CM_ "AUTOGENERATED FILE, DO NOT EDIT";

CM_ "Imported file _community.dbc starts here";
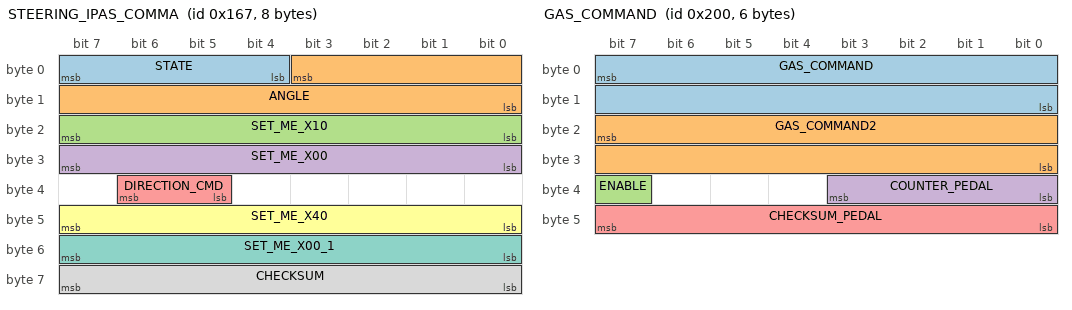
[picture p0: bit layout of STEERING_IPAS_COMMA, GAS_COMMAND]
BO_ 359 STEERING_IPAS_COMMA: 8 IPAS
 SG_ STATE : 7|4@0+ (1,0) [0|15] "" XXX
 SG_ ANGLE : 3|12@0- (1.5,0) [-510|510] "deg" XXX
 SG_ SET_ME_X10 : 23|8@0+ (1,0) [0|255] "" XXX
 SG_ SET_ME_X00 : 31|8@0+ (1,0) [0|255] "" XXX
 SG_ DIRECTION_CMD : 38|2@0+ (1,0) [0|3] "" XXX
 SG_ SET_ME_X40 : 47|8@0+ (1,0) [0|255] "" XXX
 SG_ SET_ME_X00_1 : 55|8@0+ (1,0) [0|255] "" XXX
 SG_ CHECKSUM : 63|8@0+ (1,0) [0|255] "" XXX

CM_ "BO_ STEERING_IPAS_COMMA: Copy of msg 614 so we can do angle control while the Park Assist ECU is connected (Panda spoofs 614 with 359 on connector J70). Note that addresses 0x266 and 0x167 are checksum-invariant";

BO_ 512 GAS_COMMAND: 6 EON
 SG_ GAS_COMMAND : 7|16@0+ (0.159375,-75.555) [0|1] "" INTERCEPTOR
 SG_ GAS_COMMAND2 : 23|16@0+ (0.159375,-151.111) [0|1] "" INTERCEPTOR
 SG_ ENABLE : 39|1@0+ (1,0) [0|1] "" INTERCEPTOR
 SG_ COUNTER_PEDAL : 35|4@0+ (1,0) [0|15] "" INTERCEPTOR
 SG_ CHECKSUM_PEDAL : 47|8@0+ (1,0) [0|255] "" INTERCEPTOR

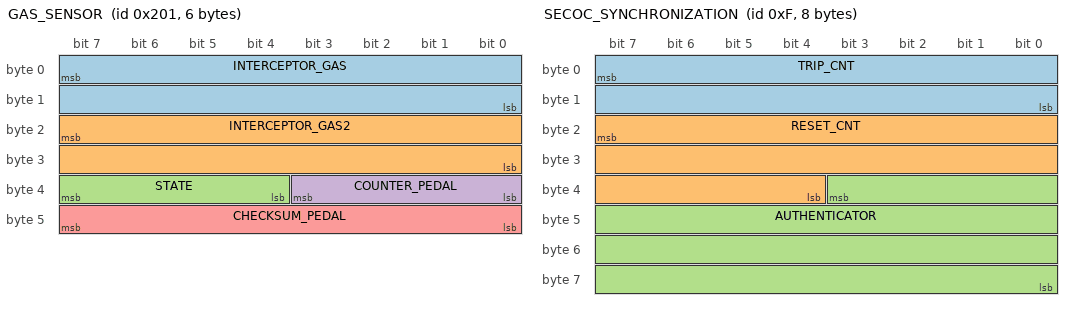
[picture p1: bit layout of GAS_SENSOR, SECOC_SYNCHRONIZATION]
BO_ 513 GAS_SENSOR: 6 INTERCEPTOR
 SG_ INTERCEPTOR_GAS : 7|16@0+ (1,0) [0|1] "" EON
 SG_ INTERCEPTOR_GAS2 : 23|16@0+ (1,0) [0|1] "" EON
 SG_ STATE : 39|4@0+ (1,0) [0|15] "" EON
 SG_ COUNTER_PEDAL : 35|4@0+ (1,0) [0|15] "" EON
 SG_ CHECKSUM_PEDAL : 47|8@0+ (1,0) [0|255] "" EON

VAL_ 513 STATE 5 "FAULT_TIMEOUT" 4 "FAULT_STARTUP" 3 "FAULT_SCE" 2 "FAULT_SEND" 1 "FAULT_BAD_CHECKSUM" 0 "NO_FAULT" ;

BO_ 35 SECONDARY_STEER_ANGLE: 8 XXX
 SG_ ZORRO_STEER : 7|24@0- (0.004901594652,0) [-500|500] "" XXX

CM_ "BO_ SECONDARY_STEER_ANGLE: ZSS is a high-precision steering angle sensor that can replace the lower resolution sensor in most TSS1 Toyotas. Learn more: https://github.com/commaai/openpilot/wiki/Toyota-Lexus#zorro-steering-sensor-zss";

BO_ 767 SDSU: 8 XXX
 SG_ FD_BUTTON : 7|1@0+ (1,0) [0|1] "" XXX
 SG_ STATE : 23|4@0+ (1,0) [0|15] "" XXX

CM_ "BO_ SDSU: The sDSU is a modified DSU for use in TSS-P Toyotas. Learn more: https://github.com/RetroPilot/ocelot/tree/main/firmware/smart_dsu";
CM_ SG_ 767 FD_BUTTON "The follow distance button signal as forwarded by the sdsu";

VAL_ 767 STATE 7 "STATE_AEB_CTRL" 6 "FAULT_INVALID" 5 "FAULT_TIMEOUT" 4 "FAULT_STARTUP" 3 "FAULT_SCE" 2 "FAULT_SEND" 1 "FAULT_BAD_CHECKSUM" 0 "NO_FAULT" ;

CM_ "toyota_rav4_prime.dbc starts here";
VERSION ""

NS_ :

BS_:

BU_: XXX DSU HCU EPS IPAS CGW BGM

BO_ 15 SECOC_SYNCHRONIZATION: 8 XXX
 SG_ TRIP_CNT : 7|16@0+ (1,0) [0|65535] "" XXX
 SG_ RESET_CNT : 23|20@0+ (1,0) [0|65535] "" XXX
 SG_ AUTHENTICATOR : 35|28@0+ (1,0) [0|268435455] "" XXX

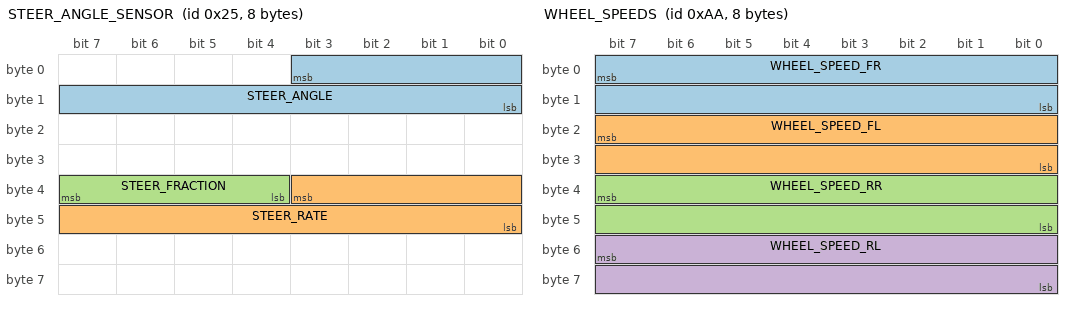
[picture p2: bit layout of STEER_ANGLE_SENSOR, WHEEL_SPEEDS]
BO_ 37 STEER_ANGLE_SENSOR: 8 XXX
 SG_ STEER_ANGLE : 3|12@0- (1.5,0) [-500|500] "deg" XXX
 SG_ STEER_RATE : 35|12@0- (1,0) [-2000|2000] "deg/s" XXX
 SG_ STEER_FRACTION : 39|4@0- (0.1,0) [-0.7|0.7] "deg" XXX

BO_ 170 WHEEL_SPEEDS: 8 XXX
 SG_ WHEEL_SPEED_FR : 7|16@0+ (0.01,-67.67) [0|250] "km/h" XXX
 SG_ WHEEL_SPEED_FL : 23|16@0+ (0.01,-67.67) [0|250] "km/h" XXX
 SG_ WHEEL_SPEED_RR : 39|16@0+ (0.01,-67.67) [0|250] "km/h" XXX
 SG_ WHEEL_SPEED_RL : 55|16@0+ (0.01,-67.67) [0|250] "km/h" XXX

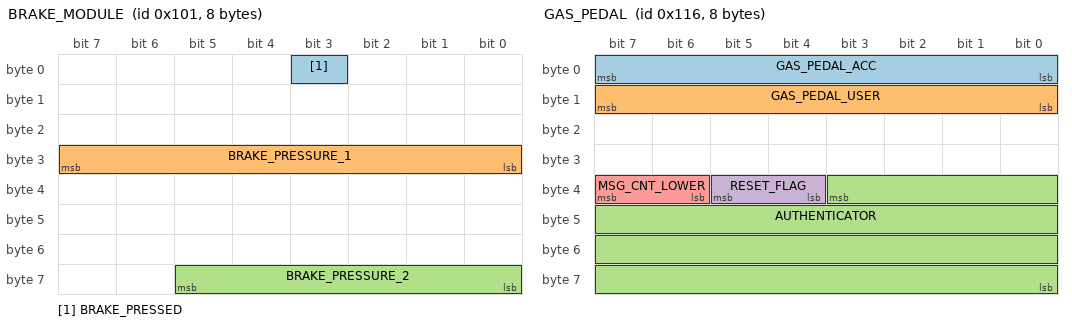
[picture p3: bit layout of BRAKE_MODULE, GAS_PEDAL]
BO_ 257 BRAKE_MODULE: 8 XXX
 SG_ BRAKE_PRESSED : 3|1@0+ (1,0) [0|1] "" XXX
 SG_ BRAKE_PRESSURE_1 : 31|8@0+ (1,0) [0|15] "" XXX
 SG_ BRAKE_PRESSURE_2 : 61|6@0+ (1,0) [0|63] "" XXX

BO_ 278 GAS_PEDAL: 8 XXX
 SG_ GAS_PEDAL_ACC : 7|8@0+ (0.005,0) [0|255] "" XXX
 SG_ GAS_PEDAL_USER : 15|8@0+ (0.005,0) [0|255] "" XXX
 SG_ AUTHENTICATOR : 35|28@0+ (1,0) [0|268435455] "" XXX
 SG_ RESET_FLAG : 37|2@0+ (1,0) [0|3] "" XXX
 SG_ MSG_CNT_LOWER : 39|2@0+ (1,0) [0|3] "" XXX

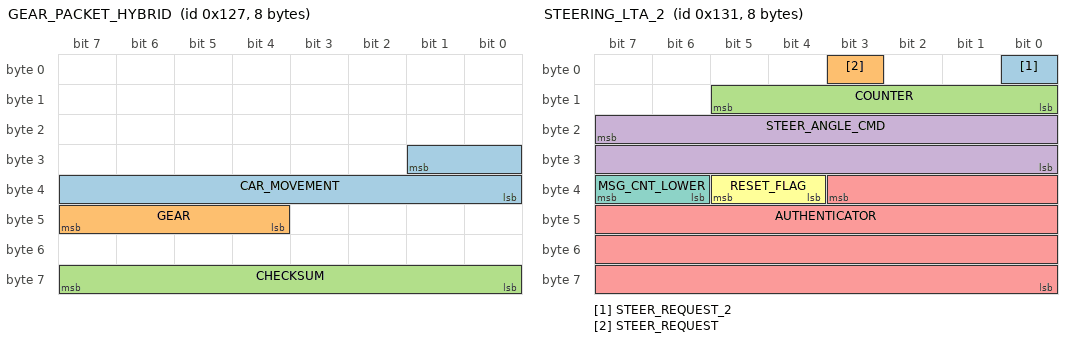
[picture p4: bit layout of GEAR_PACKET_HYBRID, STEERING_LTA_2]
BO_ 295 GEAR_PACKET_HYBRID: 8 XXX
 SG_ CAR_MOVEMENT : 25|10@0- (1,0) [0|255] "" XXX
 SG_ GEAR : 47|4@0+ (1,0) [0|15] "" XXX
 SG_ CHECKSUM : 63|8@0+ (1,0) [0|255] "" XXX

BO_ 305 STEERING_LTA_2: 8 XXX
 SG_ STEER_REQUEST_2 : 0|1@0+ (1,0) [0|1] "" XXX
 SG_ STEER_REQUEST : 3|1@0+ (1,0) [0|1] "" XXX
 SG_ COUNTER : 13|6@0+ (1,0) [0|63] "" XXX
 SG_ STEER_ANGLE_CMD : 23|16@0- (0.0573,0) [0|65535] "" XXX
 SG_ AUTHENTICATOR : 35|28@0+ (1,0) [0|268435455] "" XXX
 SG_ RESET_FLAG : 37|2@0+ (1,0) [0|3] "" XXX
 SG_ MSG_CNT_LOWER : 39|2@0+ (1,0) [0|3] "" XXX

BO_ 353 DSU_SPEED: 7 XXX
 SG_ FORWARD_SPEED : 15|16@0- (0.00390625,-30) [0|255] "km/h" XXX

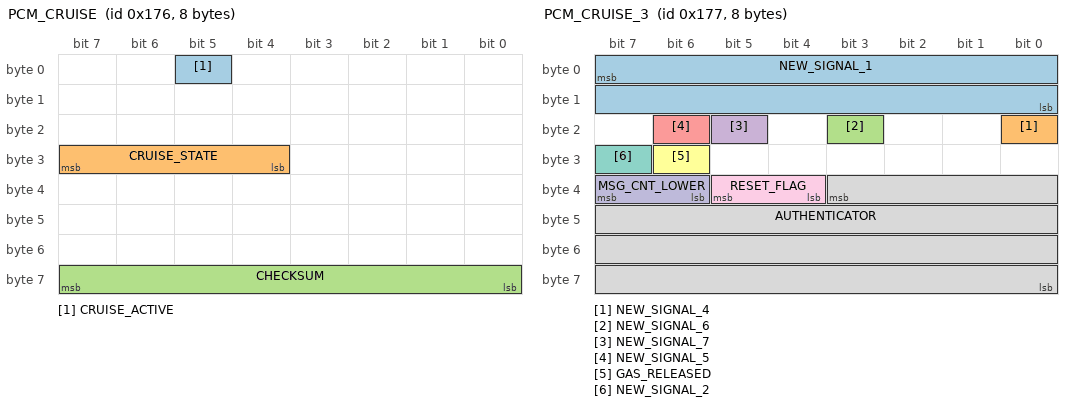
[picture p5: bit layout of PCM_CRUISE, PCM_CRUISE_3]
BO_ 374 PCM_CRUISE: 8 XXX
 SG_ CRUISE_ACTIVE : 5|1@0+ (1,0) [0|1] "" XXX
 SG_ CRUISE_STATE : 31|4@0+ (1,0) [0|1] "" XXX
 SG_ CHECKSUM : 63|8@0+ (1,0) [0|255] "" XXX

BO_ 375 PCM_CRUISE_3: 8 XXX
 SG_ NEW_SIGNAL_1 : 7|16@0- (1,0) [0|65535] "" XXX
 SG_ NEW_SIGNAL_4 : 16|1@0+ (1,0) [0|1] "" XXX
 SG_ NEW_SIGNAL_6 : 19|1@0+ (1,0) [0|1] "" XXX
 SG_ NEW_SIGNAL_7 : 21|1@0+ (1,0) [0|1] "" XXX
 SG_ NEW_SIGNAL_5 : 22|1@0+ (1,0) [0|1] "" XXX
 SG_ GAS_RELEASED : 30|1@0+ (1,0) [0|1] "" XXX
 SG_ NEW_SIGNAL_2 : 31|1@0+ (1,0) [0|1] "" XXX
 SG_ AUTHENTICATOR : 35|28@0+ (1,0) [0|268435455] "" XXX
 SG_ RESET_FLAG : 37|2@0+ (1,0) [0|3] "" XXX
 SG_ MSG_CNT_LOWER : 39|2@0+ (1,0) [0|3] "" XXX

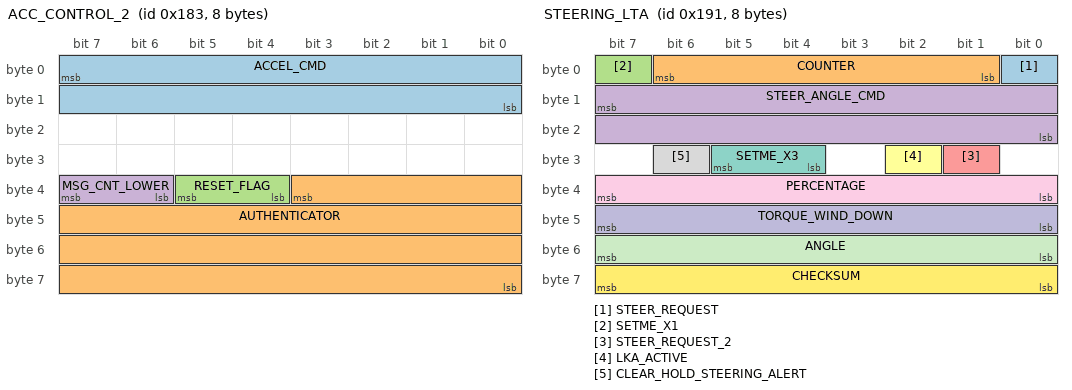
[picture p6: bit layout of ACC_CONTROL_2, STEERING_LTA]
BO_ 387 ACC_CONTROL_2: 8 XXX
 SG_ ACCEL_CMD : 7|16@0- (0.001,0) [-20|20] "m/s^2" HCU
 SG_ AUTHENTICATOR : 35|28@0+ (1,0) [0|268435455] "" XXX
 SG_ RESET_FLAG : 37|2@0+ (1,0) [0|3] "" XXX
 SG_ MSG_CNT_LOWER : 39|2@0+ (1,0) [0|3] "" XXX

BO_ 401 STEERING_LTA: 8 XXX
 SG_ STEER_REQUEST : 0|1@0+ (1,0) [0|1] "" XXX
 SG_ COUNTER : 6|6@0+ (1,0) [0|255] "" XXX
 SG_ SETME_X1 : 7|1@0+ (1,0) [0|1] "" XXX
 SG_ STEER_ANGLE_CMD : 15|16@0- (0.0573,0) [-540|540] "" XXX
 SG_ STEER_REQUEST_2 : 25|1@0+ (1,0) [0|1] "" XXX
 SG_ LKA_ACTIVE : 26|1@0+ (1,0) [0|1] "" XXX
 SG_ SETME_X3 : 29|2@0+ (1,0) [0|3] "" XXX
 SG_ CLEAR_HOLD_STEERING_ALERT : 30|1@0+ (1,0) [0|1] "" XXX
 SG_ PERCENTAGE : 39|8@0+ (1,0) [0|255] "" XXX
 SG_ TORQUE_WIND_DOWN : 47|8@0+ (1,0) [0|255] "" XXX
 SG_ ANGLE : 55|8@0- (0.5,0) [0|255] "" XXX
 SG_ CHECKSUM : 63|8@0+ (1,0) [0|255] "" XXX

BO_ 418 CRUISE_RELATED: 8 XXX
 SG_ CRUISE_ACTIVE : 7|1@0+ (1,0) [0|1] "" XXX
 SG_ CHECKSUM : 63|8@0+ (1,0) [0|255] "" XXX

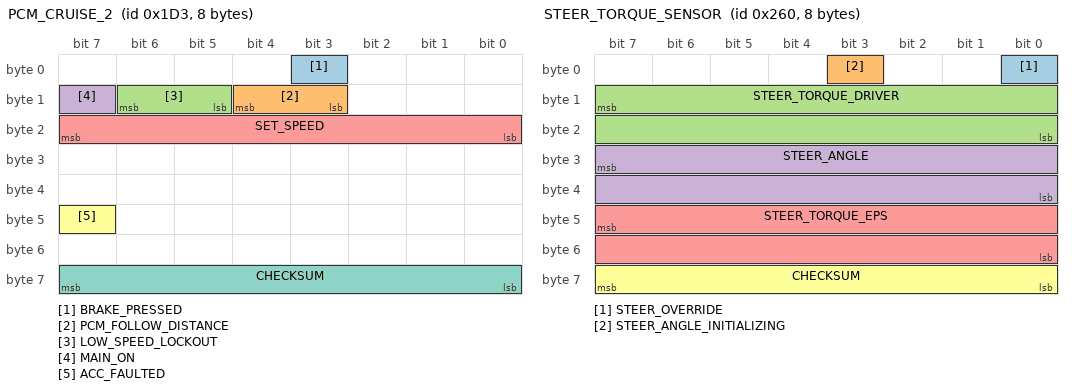
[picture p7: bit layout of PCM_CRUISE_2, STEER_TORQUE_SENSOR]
BO_ 467 PCM_CRUISE_2: 8 XXX
 SG_ BRAKE_PRESSED : 3|1@0+ (1,0) [0|1] "" XXX
 SG_ PCM_FOLLOW_DISTANCE : 12|2@0+ (1,0) [0|3] "" XXX
 SG_ LOW_SPEED_LOCKOUT : 14|2@0+ (1,0) [0|3] "" XXX
 SG_ MAIN_ON : 15|1@0+ (1,0) [0|1] "" XXX
 SG_ SET_SPEED : 23|8@0+ (1,0) [0|255] "km/h" XXX
 SG_ ACC_FAULTED : 47|1@0+ (1,0) [0|1] "" XXX
 SG_ CHECKSUM : 63|8@0+ (1,0) [0|255] "" XXX

BO_ 608 STEER_TORQUE_SENSOR: 8 XXX
 SG_ STEER_OVERRIDE : 0|1@0+ (1,0) [0|1] "" XXX
 SG_ STEER_ANGLE_INITIALIZING : 3|1@0+ (1,0) [0|1] "" XXX
 SG_ STEER_TORQUE_DRIVER : 15|16@0- (1,0) [-32768|32767] "" XXX
 SG_ STEER_ANGLE : 31|16@0- (0.0573,0) [-500|500] "" XXX
 SG_ STEER_TORQUE_EPS : 47|16@0- (1,0) [-32768|32767] "" XXX
 SG_ CHECKSUM : 63|8@0+ (1,0) [0|255] "" XXX

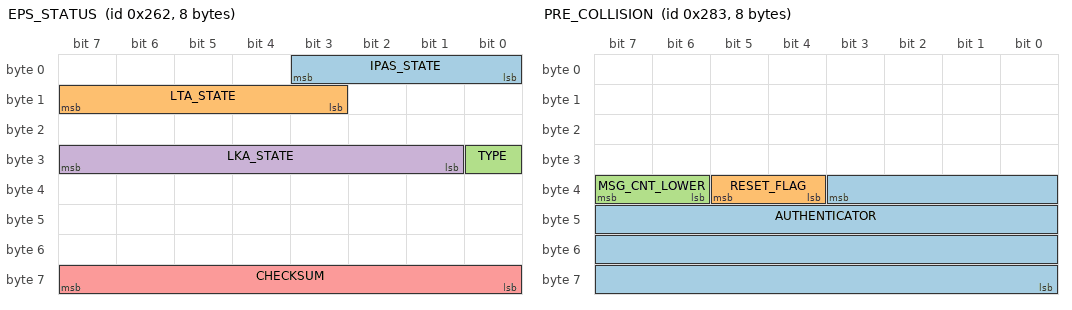
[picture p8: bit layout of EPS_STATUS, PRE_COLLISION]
BO_ 610 EPS_STATUS: 8 EPS
 SG_ IPAS_STATE : 3|4@0+ (1,0) [0|15] "" XXX
 SG_ LTA_STATE : 15|5@0+ (1,0) [0|31] "" XXX
 SG_ TYPE : 24|1@0+ (1,0) [0|1] "" XXX
 SG_ LKA_STATE : 31|7@0+ (1,0) [0|127] "" XXX
 SG_ CHECKSUM : 63|8@0+ (1,0) [0|255] "" XXX

BO_ 643 PRE_COLLISION: 8 DSU
 SG_ AUTHENTICATOR : 35|28@0+ (1,0) [0|268435455] "" XXX
 SG_ RESET_FLAG : 37|2@0+ (1,0) [0|3] "" XXX
 SG_ MSG_CNT_LOWER : 39|2@0+ (1,0) [0|3] "" XXX

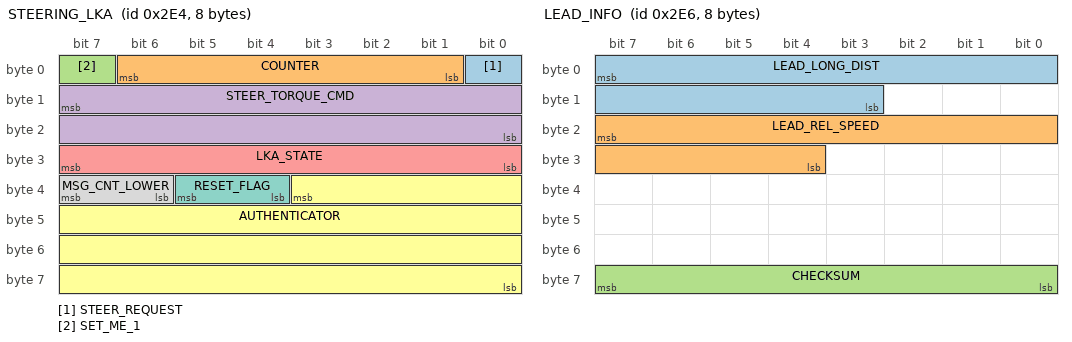
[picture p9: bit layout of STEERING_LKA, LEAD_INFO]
BO_ 740 STEERING_LKA: 8 XXX
 SG_ STEER_REQUEST : 0|1@0+ (1,0) [0|1] "" XXX
 SG_ COUNTER : 6|6@0+ (1,0) [0|63] "" XXX
 SG_ SET_ME_1 : 7|1@0+ (1,0) [0|1] "" XXX
 SG_ STEER_TORQUE_CMD : 15|16@0- (1,0) [0|65535] "" XXX
 SG_ LKA_STATE : 31|8@0+ (1,0) [0|255] "" XXX
 SG_ AUTHENTICATOR : 35|28@0+ (1,0) [0|268435455] "" XXX
 SG_ RESET_FLAG : 37|2@0+ (1,0) [0|3] "" XXX
 SG_ MSG_CNT_LOWER : 39|2@0+ (1,0) [0|3] "" XXX

BO_ 742 LEAD_INFO: 8 DSU
 SG_ LEAD_LONG_DIST : 7|13@0+ (0.05,0) [0|300] "m" HCU
 SG_ LEAD_REL_SPEED : 23|12@0- (0.025,0) [-100|100] "m/s" HCU
 SG_ CHECKSUM : 63|8@0+ (1,0) [0|255] "" HCU

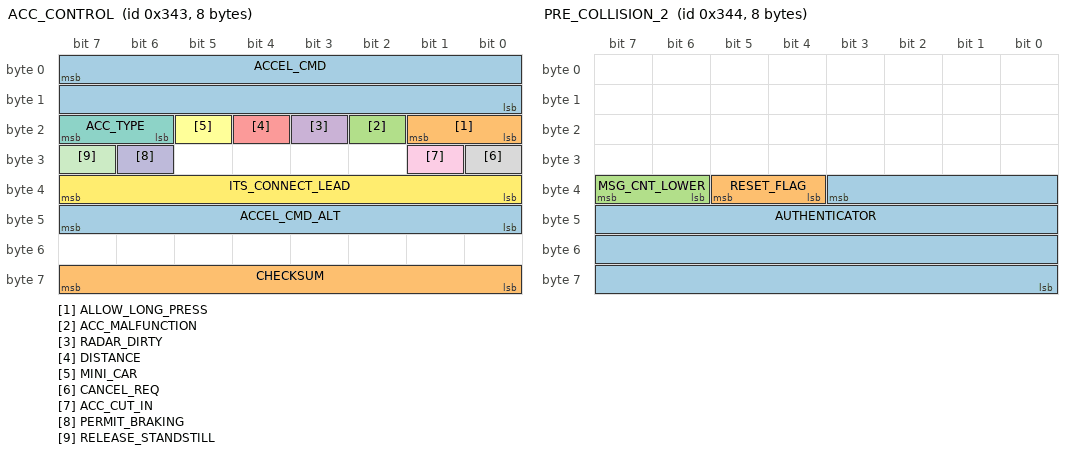
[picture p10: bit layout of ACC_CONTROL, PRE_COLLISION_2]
BO_ 835 ACC_CONTROL: 8 DSU
 SG_ ACCEL_CMD : 7|16@0- (0.001,0) [-20|20] "m/s^2" HCU
 SG_ ALLOW_LONG_PRESS : 17|2@0+ (1,0) [0|2] "" XXX
 SG_ ACC_MALFUNCTION : 18|1@0+ (1,0) [0|0] "" XXX
 SG_ RADAR_DIRTY : 19|1@0+ (1,0) [0|1] "" XXX
 SG_ DISTANCE : 20|1@0+ (1,0) [0|1] "" XXX
 SG_ MINI_CAR : 21|1@0+ (1,0) [0|1] "" XXX
 SG_ ACC_TYPE : 23|2@0+ (1,0) [0|3] "" HCU
 SG_ CANCEL_REQ : 24|1@0+ (1,0) [0|1] "" HCU
 SG_ ACC_CUT_IN : 25|1@0+ (1,0) [0|1] "" XXX
 SG_ PERMIT_BRAKING : 30|1@0+ (1,0) [0|1] "" HCU
 SG_ RELEASE_STANDSTILL : 31|1@0+ (1,0) [0|1] "" HCU
 SG_ ITS_CONNECT_LEAD : 39|8@0+ (1,0) [0|1] "" Vector__XXX
 SG_ ACCEL_CMD_ALT : 47|8@0- (0.05,0) [0|0] "m/s^2" XXX
 SG_ CHECKSUM : 63|8@0+ (1,0) [0|255] "" XXX

BO_ 836 PRE_COLLISION_2: 8 DSU
 SG_ AUTHENTICATOR : 35|28@0+ (1,0) [0|268435455] "" XXX
 SG_ RESET_FLAG : 37|2@0+ (1,0) [0|3] "" XXX
 SG_ MSG_CNT_LOWER : 39|2@0+ (1,0) [0|3] "" XXX

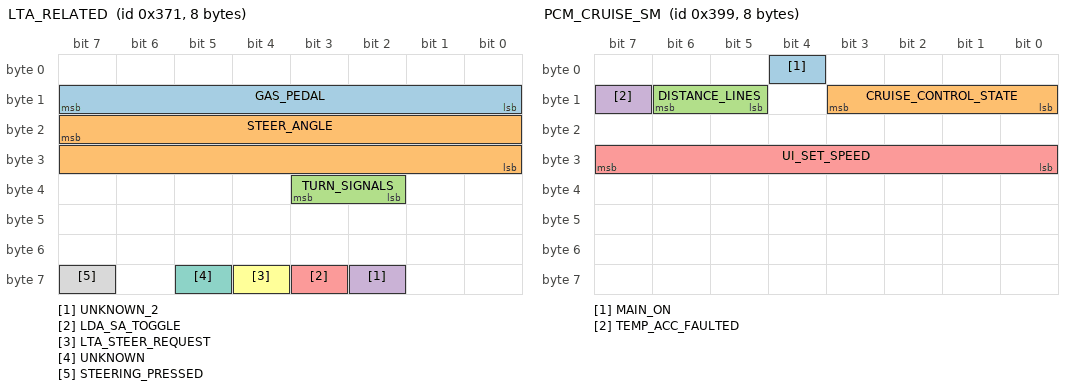
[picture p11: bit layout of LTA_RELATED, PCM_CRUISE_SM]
BO_ 881 LTA_RELATED: 8 FCM
 SG_ GAS_PEDAL : 15|8@0+ (0.005,0) [0|1] "" XXX
 SG_ STEER_ANGLE : 23|16@0- (0.0573,0) [-500|500] "" XXX
 SG_ TURN_SIGNALS : 35|2@0+ (1,0) [0|3] "" XXX
 SG_ UNKNOWN_2 : 58|1@0+ (1,0) [0|1] "" XXX
 SG_ LDA_SA_TOGGLE : 59|1@0+ (1,0) [0|1] "" XXX
 SG_ LTA_STEER_REQUEST : 60|1@0+ (1,0) [0|1] "" XXX
 SG_ UNKNOWN : 61|1@0+ (1,0) [0|1] "" XXX
 SG_ STEERING_PRESSED : 63|1@0+ (1,0) [0|1] "" XXX

BO_ 921 PCM_CRUISE_SM: 8 XXX
 SG_ MAIN_ON : 4|1@0+ (1,0) [0|1] "" XXX
 SG_ CRUISE_CONTROL_STATE : 11|4@0+ (1,0) [0|15] "" XXX
 SG_ DISTANCE_LINES : 14|2@0+ (1,0) [0|3] "" XXX
 SG_ TEMP_ACC_FAULTED : 15|1@0+ (1,0) [0|1] "" XXX
 SG_ UI_SET_SPEED : 31|8@0+ (1,0) [0|255] "" XXX

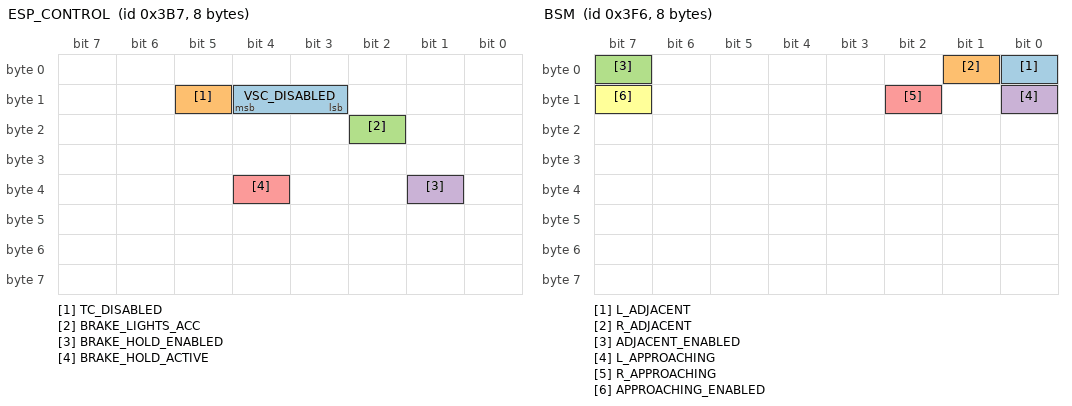
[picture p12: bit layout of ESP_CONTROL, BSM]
BO_ 951 ESP_CONTROL: 8 ESP
 SG_ VSC_DISABLED : 12|2@0+ (1,0) [0|1] "" XXX
 SG_ TC_DISABLED : 13|1@0+ (1,0) [0|1] "" XXX
 SG_ BRAKE_LIGHTS_ACC : 18|1@0+ (1,0) [0|1] "" XXX
 SG_ BRAKE_HOLD_ENABLED : 33|1@1+ (1,0) [0|1] "" XXX
 SG_ BRAKE_HOLD_ACTIVE : 36|1@0+ (1,0) [0|1] "" XXX

BO_ 1014 BSM: 8 XXX
 SG_ L_ADJACENT : 0|1@0+ (1,0) [0|1] "" XXX
 SG_ R_ADJACENT : 1|1@0+ (1,0) [0|1] "" XXX
 SG_ ADJACENT_ENABLED : 7|1@0+ (1,0) [0|1] "" XXX
 SG_ L_APPROACHING : 8|1@0+ (1,0) [0|1] "" XXX
 SG_ R_APPROACHING : 10|1@0+ (1,0) [0|1] "" XXX
 SG_ APPROACHING_ENABLED : 15|1@0+ (1,0) [0|1] "" XXX

BO_ 1020 SOLAR_SENSOR: 8 XXX
 SG_ LUX_SENSOR : 55|13@0+ (1,0) [0|0] "" XXX

BO_ 1041 PCS_HUD: 8 DSU
 SG_ FCW : 4|1@0+ (1,0) [0|1] "" XXX
 SG_ PCS_INDICATOR : 7|2@0+ (1,0) [0|3] "" XXX
 SG_ SET_ME_X20 : 15|8@0+ (1,0) [0|1] "" XXX
 SG_ PCS_DUST : 34|1@0+ (1,0) [0|0] "" XXX
 SG_ PCS_TEMP : 35|1@0+ (1,0) [0|0] "" XXX
 SG_ SET_ME_X10 : 39|8@0+ (1,0) [0|1] "" XXX
 SG_ PCS_OFF : 40|1@0+ (1,0) [0|0] "" XXX
 SG_ PCS_DUST2 : 41|1@0+ (1,0) [0|0] "" XXX
 SG_ PCS_TEMP2 : 42|1@0+ (1,0) [0|0] "" XXX
 SG_ FRD_ADJ : 53|3@0+ (1,0) [0|0] "" XXX
 SG_ PCS_SENSITIVITY : 55|8@0+ (1,0) [0|1] "" XXX

BO_ 1042 LKAS_HUD: 8 DSU
 SG_ BARRIERS : 1|2@0+ (1,0) [0|3] "" XXX
 SG_ RIGHT_LINE : 3|2@0+ (1,0) [0|3] "" XXX
 SG_ LEFT_LINE : 5|2@0+ (1,0) [0|3] "" XXX
 SG_ LKAS_STATUS : 7|2@0+ (1,0) [0|3] "" XXX
 SG_ LDA_ALERT : 9|2@0+ (1,0) [0|3] "" XXX
 SG_ LDW_EXIST : 10|1@0+ (1,0) [0|1] "" XXX
 SG_ TWO_BEEPS : 12|1@0+ (1,0) [0|1] "" XXX
 SG_ ADJUSTING_CAMERA : 13|1@0+ (1,0) [0|1] "" XXX
 SG_ LDA_UNAVAILABLE_QUIET : 14|1@0+ (1,0) [0|1] "" XXX
 SG_ LDA_MALFUNCTION : 15|1@0+ (1,0) [0|1] "" XXX
 SG_ LDA_UNAVAILABLE : 16|1@0+ (1,0) [0|1] "" XXX
 SG_ LDA_SENSITIVITY : 18|2@0+ (1,0) [0|3] "" XXX
 SG_ LDA_SA_TOGGLE : 20|2@0+ (1,0) [0|3] "" XXX
 SG_ LDA_MESSAGES : 23|3@0+ (1,0) [0|1] "" XXX
 SG_ LDA_ON_MESSAGE : 31|2@0+ (1,0) [0|3] "" XXX
 SG_ REPEATED_BEEPS : 32|1@0+ (1,0) [0|1] "" XXX
 SG_ SET_ME_X01 : 42|1@0+ (1,0) [0|1] "" XXX
 SG_ LANE_SWAY_TOGGLE : 43|1@0+ (1,0) [0|1] "" XXX
 SG_ LANE_SWAY_SENSITIVITY : 45|2@0+ (1,0) [0|3] "" XXX
 SG_ TAKE_CONTROL : 46|1@0+ (1,0) [0|1] "" XXX
 SG_ LDA_FRONT_CAMERA_BLOCKED : 47|1@0+ (1,0) [0|1] "" XXX
 SG_ LANE_SWAY_BUZZER : 50|2@0+ (1,0) [0|0] "" XXX
 SG_ LANE_SWAY_FLD : 53|3@0+ (1,0) [0|7] "" XXX
 SG_ LANE_SWAY_WARNING : 55|2@0+ (1,0) [0|3] "" XXX
 SG_ SET_ME_X02 : 63|8@0+ (1,0) [0|1] "" XXX

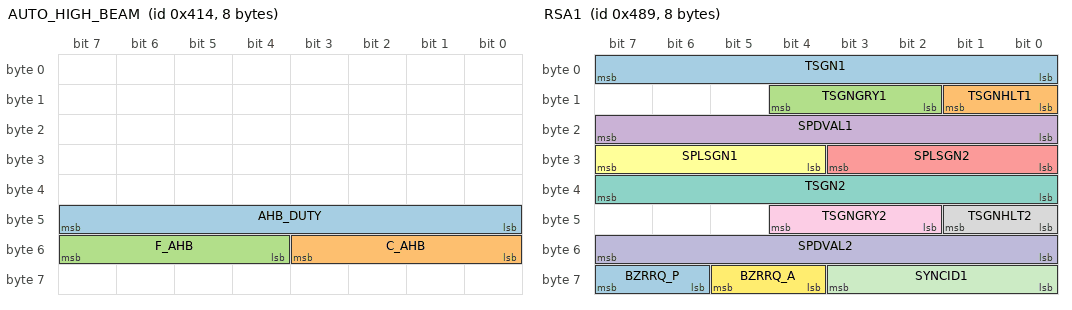
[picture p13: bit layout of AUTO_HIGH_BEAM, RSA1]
BO_ 1044 AUTO_HIGH_BEAM: 8 FCM
 SG_ AHB_DUTY : 47|8@0+ (0.5,0) [0|0] "%" Vector__XXX
 SG_ C_AHB : 51|4@0+ (1,0) [0|0] "" Vector__XXX
 SG_ F_AHB : 55|4@0+ (1,0) [0|0] "" Vector__XXX

BO_ 1161 RSA1: 8 FCM
 SG_ TSGN1 : 7|8@0+ (1,0) [0|0] "" XXX
 SG_ TSGNHLT1 : 9|2@0+ (1,0) [0|0] "" XXX
 SG_ TSGNGRY1 : 12|3@0+ (1,0) [0|0] "" XXX
 SG_ SPDVAL1 : 23|8@0+ (1,0) [0|0] "km/h" XXX
 SG_ SPLSGN2 : 27|4@0+ (1,0) [0|0] "" XXX
 SG_ SPLSGN1 : 31|4@0+ (1,0) [0|0] "" XXX
 SG_ TSGN2 : 39|8@0+ (1,0) [0|0] "" XXX
 SG_ TSGNHLT2 : 41|2@0+ (1,0) [0|0] "" XXX
 SG_ TSGNGRY2 : 44|3@0+ (1,0) [0|0] "" XXX
 SG_ SPDVAL2 : 55|8@0+ (1,0) [0|0] "" XXX
 SG_ SYNCID1 : 59|4@0+ (1,0) [0|0] "" XXX
 SG_ BZRRQ_A : 61|2@0+ (1,0) [0|0] "" XXX
 SG_ BZRRQ_P : 63|2@0+ (1,0) [0|0] "" XXX

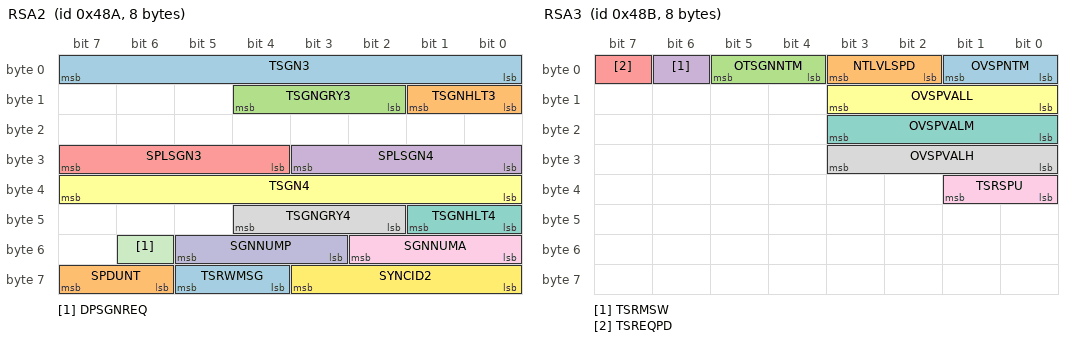
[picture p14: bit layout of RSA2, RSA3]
BO_ 1162 RSA2: 8 FCM
 SG_ TSGN3 : 7|8@0+ (1,0) [0|0] "" XXX
 SG_ TSGNHLT3 : 9|2@0+ (1,0) [0|0] "" XXX
 SG_ TSGNGRY3 : 12|3@0+ (1,0) [0|0] "" XXX
 SG_ SPLSGN4 : 27|4@0+ (1,0) [0|0] "" XXX
 SG_ SPLSGN3 : 31|4@0+ (1,0) [0|0] "" XXX
 SG_ TSGN4 : 39|8@0+ (1,0) [0|0] "" XXX
 SG_ TSGNHLT4 : 41|2@0+ (1,0) [0|0] "" XXX
 SG_ TSGNGRY4 : 44|3@0+ (1,0) [0|0] "" XXX
 SG_ SGNNUMA : 50|3@0+ (1,0) [0|0] "" XXX
 SG_ SGNNUMP : 53|3@0+ (1,0) [0|0] "" XXX
 SG_ DPSGNREQ : 54|1@0+ (1,0) [0|0] "" XXX
 SG_ SYNCID2 : 59|4@0+ (1,0) [0|0] "" XXX
 SG_ TSRWMSG : 61|2@0+ (1,0) [0|0] "" XXX
 SG_ SPDUNT : 63|2@0+ (1,0) [0|0] "" XXX

BO_ 1163 RSA3: 8 FCM
 SG_ OVSPNTM : 1|2@0+ (1,0) [0|0] "" XXX
 SG_ NTLVLSPD : 3|2@0+ (1,0) [0|0] "" XXX
 SG_ OTSGNNTM : 5|2@0+ (1,0) [0|0] "" XXX
 SG_ TSRMSW : 6|1@0+ (1,0) [0|0] "" XXX
 SG_ TSREQPD : 7|1@0+ (1,0) [0|0] "" XXX
 SG_ OVSPVALL : 11|4@0+ (1,-5) [0|0] "" XXX
 SG_ OVSPVALM : 19|4@0+ (1,-5) [0|0] "" XXX
 SG_ OVSPVALH : 27|4@0+ (1,-5) [0|0] "" XXX
 SG_ TSRSPU : 33|2@0+ (1,0) [0|0] "" XXX

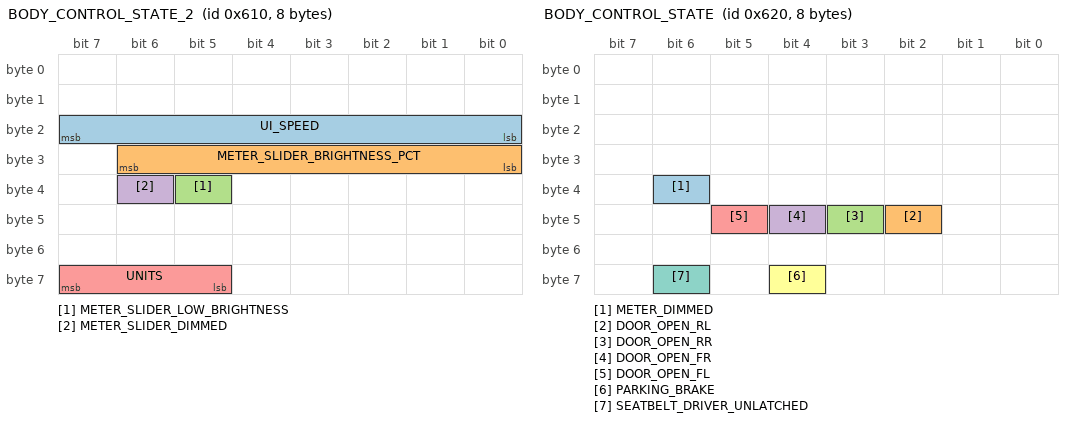
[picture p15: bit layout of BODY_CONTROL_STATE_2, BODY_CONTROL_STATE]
BO_ 1552 BODY_CONTROL_STATE_2: 8 XXX
 SG_ UI_SPEED : 23|8@0+ (1,0) [0|255] "" XXX
 SG_ METER_SLIDER_BRIGHTNESS_PCT : 30|7@0+ (1,0) [12|100] "%" XXX
 SG_ METER_SLIDER_LOW_BRIGHTNESS : 37|1@0+ (1,0) [0|1] "" XXX
 SG_ METER_SLIDER_DIMMED : 38|1@0+ (1,0) [0|1] "" XXX
 SG_ UNITS : 63|3@0+ (1,0) [1|4] "" XXX

BO_ 1553 UI_SETTING: 8 XXX
 SG_ UNITS : 26|2@0+ (1,0) [0|3] "" XXX
 SG_ ODOMETER : 39|32@0+ (1,0) [0|1048575] "" XXX

BO_ 1556 BLINKERS_STATE: 8 XXX
 SG_ HAZARD_LIGHT : 27|1@0+ (1,0) [0|1] "" XXX
 SG_ TURN_SIGNALS : 29|2@0+ (1,0) [0|3] "" XXX

BO_ 1568 BODY_CONTROL_STATE: 8 XXX
 SG_ METER_DIMMED : 38|1@0+ (1,0) [0|1] "" XXX
 SG_ DOOR_OPEN_RL : 42|1@0+ (1,0) [0|1] "" XXX
 SG_ DOOR_OPEN_RR : 43|1@0+ (1,0) [0|1] "" XXX
 SG_ DOOR_OPEN_FR : 44|1@0+ (1,0) [0|1] "" XXX
 SG_ DOOR_OPEN_FL : 45|1@0+ (1,0) [0|1] "" XXX
 SG_ PARKING_BRAKE : 60|1@0+ (1,0) [0|1] "" XXX
 SG_ SEATBELT_DRIVER_UNLATCHED : 62|1@0+ (1,0) [0|1] "" XXX

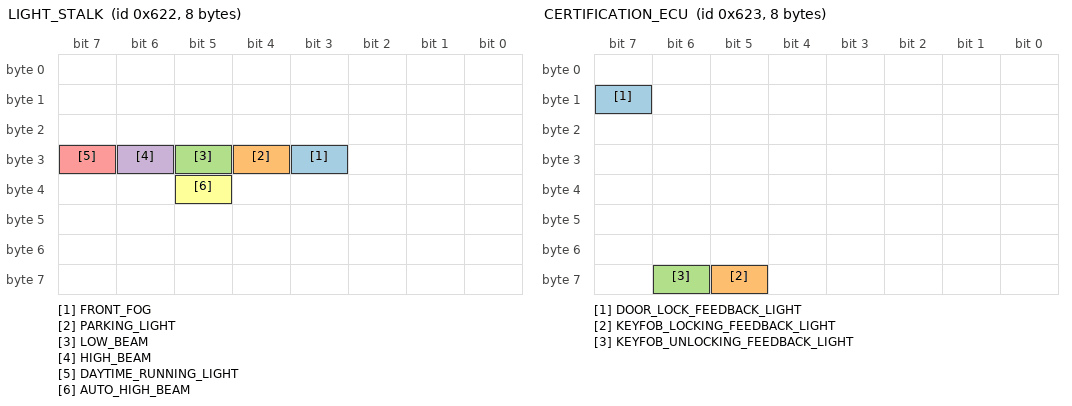
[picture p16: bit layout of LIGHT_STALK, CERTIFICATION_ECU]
BO_ 1570 LIGHT_STALK: 8 SCM
 SG_ FRONT_FOG : 27|1@0+ (1,0) [0|1] "" XXX
 SG_ PARKING_LIGHT : 28|1@0+ (1,0) [0|1] "" XXX
 SG_ LOW_BEAM : 29|1@0+ (1,0) [0|1] "" XXX
 SG_ HIGH_BEAM : 30|1@0+ (1,0) [0|1] "" XXX
 SG_ DAYTIME_RUNNING_LIGHT : 31|1@0+ (1,0) [0|1] "" XXX
 SG_ AUTO_HIGH_BEAM : 37|1@0+ (1,0) [0|1] "" XXX

BO_ 1571 CERTIFICATION_ECU: 8 CGW
 SG_ DOOR_LOCK_FEEDBACK_LIGHT : 15|1@0+ (1,0) [0|0] "" XXX
 SG_ KEYFOB_LOCKING_FEEDBACK_LIGHT : 61|1@0+ (1,0) [0|0] "" XXX
 SG_ KEYFOB_UNLOCKING_FEEDBACK_LIGHT : 62|1@0+ (1,0) [0|0] "" XXX

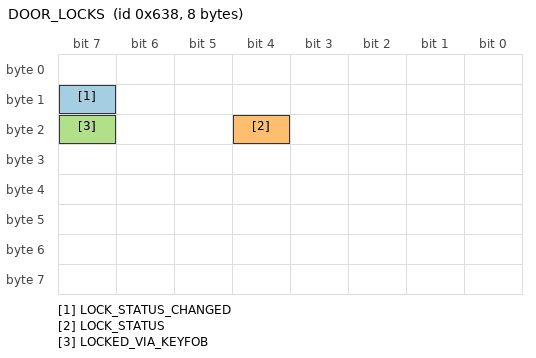
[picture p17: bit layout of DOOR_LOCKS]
BO_ 1592 DOOR_LOCKS: 8 XXX
 SG_ LOCK_STATUS_CHANGED : 15|1@0+ (1,0) [0|1] "" XXX
 SG_ LOCK_STATUS : 20|1@0+ (1,0) [0|1] "" XXX
 SG_ LOCKED_VIA_KEYFOB : 23|1@0+ (1,0) [0|1] "" XXX

CM_ SG_ 37 STEER_RATE "factor is tbd";
CM_ SG_ 37 STEER_FRACTION "1/15th of the signal STEER_ANGLE, which is 1.5 deg; note that 0x8 is never set";
CM_ SG_ 305 STEER_ANGLE_CMD "Used in place of STEERING_LTA.STEER_ANGLE_CMD on SecOC cars";
CM_ SG_ 387 ACCEL_CMD "Used in place of ACC_CONTROL.ACCEL_CMD on SecOC cars";
CM_ SG_ 401 STEER_REQUEST "enable bit for steering, 1 to steer, 0 to not";
CM_ SG_ 401 SETME_X1 "usually 1, seen at 0 on some South American Corollas indicating lack of stock Lane Tracing Assist";
CM_ SG_ 401 STEER_ANGLE_CMD "desired angle, OEM steers up to 95 degrees, no angle limit but torque will bottom out";
CM_ SG_ 401 STEER_REQUEST_2 "enable bit for steering, 1 to steer, 0 to not";
CM_ SG_ 401 LKA_ACTIVE "1 when using LTA for LKA";
CM_ SG_ 401 SETME_X3 "almost completely correlates with Toyota Safety Sense version, but may instead describe max torque when using LTA. if TSS 2.5 or 2022 RAV4, this is always 1. if TSS 2.0 this is always 3 (or 0 on Alphard, Highlander, NX)";
CM_ SG_ 401 CLEAR_HOLD_STEERING_ALERT "set to 1 when user clears LKAS_HUD->LDA_ALERT ('Hold Steering') by applying torque to steering wheel";
CM_ SG_ 401 PERCENTAGE "driver override percentage (0-100), very close to steeringPressed in OP";
CM_ SG_ 401 TORQUE_WIND_DOWN "used to wind down torque on user override";
CM_ SG_ 401 ANGLE "angle of car relative to lane center on LTA camera";
CM_ SG_ 467 LOW_SPEED_LOCKOUT "in low speed lockout, system would always disengage below 28mph";
CM_ SG_ 467 SET_SPEED "43 km/h are shown as 28 mph, so conversion isn't perfect";
CM_ SG_ 467 ACC_FAULTED "1 when ACC is faulted and the PCM disallows engagement";
CM_ SG_ 608 STEER_OVERRIDE "set when driver torque exceeds a certain value";
CM_ SG_ 608 STEER_TORQUE_DRIVER "driver torque";
CM_ SG_ 610 TYPE "seems 1 on Corolla, 0 on all others";
CM_ SG_ 835 ALLOW_LONG_PRESS "Enable Toyota's factory set speed increment behaviour, available on both metrics cars and imperial unit cars";
CM_ SG_ 835 ACC_MALFUNCTION "display ACC fault on dash if set to 1";
CM_ SG_ 835 RADAR_DIRTY "Display Clean Radar Sensor message on HUD";
CM_ SG_ 835 DISTANCE "Cycle through ACC following distance from long, mid, short when set to 1";
CM_ SG_ 835 ACC_TYPE "if 2, car is likely to have a permanent low speed lockout. 1 is ok";
CM_ SG_ 835 ACC_CUT_IN "Display blinking yellow lead if set to 1";
CM_ SG_ 835 PERMIT_BRAKING "Original ACC has this going high when a car in front is detected. In openpilot and before the PERMIT_BRAKING name, this was 'SET_ME_1' and is hardcoded to be high. Unsure if only informational or has an effect though existing usage in openpilot is to always set it to 1. Originally 'PMTBRKG' in the leaked toyota_2017_ref_pt.dbc file and name expansion speculated to be PerMiT BRaKinG.";
CM_ SG_ 835 ITS_CONNECT_LEAD "Displayed when lead car is capable of ITS Connect";
CM_ SG_ 835 ACCEL_CMD_ALT "Copy of main ACCEL_CMD, but across 8 bits instead of 16 bits like ACCEL_CMD. Unsure if only informational or has an effect. Likely informational as existing openpilot sets this to 0 and no loss of functionality observed. Originally 'AT_RAW' in leaked toyota_2017_ref_pt.dbc file.";
CM_ SG_ 881 GAS_PEDAL "not set on all cars, only seen on TSS 2.5 Camry Hybrid so far";
CM_ SG_ 881 STEER_ANGLE "matches STEER_TORQUE_SENSOR->STEER_ANGLE";
CM_ SG_ 881 TURN_SIGNALS "flipped on some cars";
CM_ SG_ 881 LDA_SA_TOGGLE "not applicable for all cars";
CM_ SG_ 881 LTA_STEER_REQUEST "only applicable for TSS 2.5: matches STEERING_LTA->STEER_REQUEST";
CM_ SG_ 881 UNKNOWN "related to steering wheel angle";
CM_ SG_ 881 STEERING_PRESSED "only applicable for TSS 2.5: low sensitivity steering wheel pressed by driver signal";
CM_ SG_ 921 TEMP_ACC_FAULTED "1 when the UI is displaying or playing fault-related alerts or sounds. Also 1 when pressing main on.";
CM_ SG_ 921 UI_SET_SPEED "set speed shown in the vehicle's UI with the vehicle's unit";
CM_ SG_ 951 BRAKE_LIGHTS_ACC "brake lights when ACC commands decel";
CM_ SG_ 1014 L_ADJACENT "vehicle adjacent left side of car. enabled above 10mph, regardless of ADJACENT_ENABLED or APPROACHING_ENABLED";
CM_ SG_ 1014 R_ADJACENT "vehicle adjacent right side of car. enabled above 10mph, regardless of ADJACENT_ENABLED or APPROACHING_ENABLED";
CM_ SG_ 1014 ADJACENT_ENABLED "when BSM is enabled in settings, this is on along with APPROACHING_ENABLED. this controls bsm alert visibility";
CM_ SG_ 1014 L_APPROACHING "vehicle approaching from left side of car. enabled above 10mph, regardless of ADJACENT_ENABLED or APPROACHING_ENABLED";
CM_ SG_ 1014 R_APPROACHING "vehicle approaching from right side of car. enabled above 10mph, regardless of ADJACENT_ENABLED or APPROACHING_ENABLED";
CM_ SG_ 1014 APPROACHING_ENABLED "when BSM is enabled in settings, this is on along with ADJACENT_ENABLED. this controls bsm alert visibility";
CM_ SG_ 1041 PCS_INDICATOR "Pre-Collision System Indicator";
CM_ SG_ 1041 PCS_DUST "alert: Front Camera Low Visibility Unavailable See Owner's Manual";
CM_ SG_ 1041 PCS_TEMP "alert: Front Camera Out of Temperature Range Unavailable Wait until Normal Temperature";
CM_ SG_ 1041 PCS_DUST2 "alert: Pre-Collision System Radar Sensor Blocked Unavailable Clean Radar Sensor";
CM_ SG_ 1041 PCS_TEMP2 "alert: Pre-Collision System Out of Temperature Range Unavailable See Owner's Manual";
CM_ SG_ 1041 FRD_ADJ "alert: ERROR ADJUSTING FRONT RADAR BEAM";
CM_ SG_ 1041 PCS_SENSITIVITY "Pre-Collision System Sensitivity";
CM_ SG_ 1042 LDW_EXIST "Unclear what this is, it's usually set to 0";
CM_ SG_ 1042 LDA_UNAVAILABLE_QUIET "LDA toggles and sensitivity settings are greyed out if set to 1";
CM_ SG_ 1042 LDA_SENSITIVITY "LDA Sensitivity";
CM_ SG_ 1042 LDA_SA_TOGGLE "LDA Steering Assist Toggle";
CM_ SG_ 1042 LDA_MESSAGES "Various LDA Messages";
CM_ SG_ 1042 LDA_ON_MESSAGE "Display LDA Turned ON message";
CM_ SG_ 1042 REPEATED_BEEPS "LDA audible warning";
CM_ SG_ 1042 SET_ME_X01 "empty bit on leaked dbc, always set to 1 during normal operations";
CM_ SG_ 1042 LANE_SWAY_TOGGLE "Lane Sway Warning System SWS Switch";
CM_ SG_ 1042 TAKE_CONTROL "Please Control Steering Wheel warning";
CM_ SG_ 1042 LDA_FRONT_CAMERA_BLOCKED "originally LDAFCVB, LDA related settings are greyed out if set to 1";
CM_ SG_ 1042 LANE_SWAY_BUZZER "Similar to TWO_BEEPS";
CM_ SG_ 1042 LANE_SWAY_FLD "Unknown signal for Lane Sway Warning System, set to 7 on stock system when SWS is enabled, 0 when SWS is disabled";
CM_ SG_ 1042 LANE_SWAY_WARNING "Lane Sway Warning System Triggered";
CM_ SG_ 1042 SET_ME_X02 "empty bit on leaked dbc, always set to 2 during normal operations";
CM_ SG_ 1161 SPDVAL1 "Numbers 0-199 is displayed, 200-254 displays circle without number and 255 is for no limit.";
CM_ SG_ 1161 SPDVAL2 "conditional speed value 70";
CM_ SG_ 1161 SYNCID1 "counter from 1 to f at 1 Hz";
CM_ SG_ 1162 SGNNUMP "1 if SPDVAL1 is set, otherwise 0";
CM_ SG_ 1162 SYNCID2 "counter from 1 to f at 1 Hz";
CM_ SG_ 1163 OVSPNTM "always 3";
CM_ SG_ 1163 NTLVLSPD "always 3";
CM_ SG_ 1163 OTSGNNTM "always 3";
CM_ SG_ 1163 TSRMSW "always 1";
CM_ SG_ 1163 TSREQPD "always 1";
CM_ SG_ 1163 OVSPVALL "-5 at start then 2 after 2 seconds";
CM_ SG_ 1163 OVSPVALM "-5 at start then 5 after 2 seconds";
CM_ SG_ 1163 OVSPVALH "-5 at start then 10 after 2 seconds";
CM_ SG_ 1163 TSRSPU "always 1";
CM_ SG_ 1552 UI_SPEED "Does not appear to match dash";
CM_ SG_ 1552 METER_SLIDER_BRIGHTNESS_PCT "Combination display brightness setting, scales from 12 per cent to 100 per cent, reflects combination meter settings only, not linked with headlight state";
CM_ SG_ 1552 METER_SLIDER_LOW_BRIGHTNESS "Combination display low brightness mode, also controls footwell lighting";
CM_ SG_ 1552 METER_SLIDER_DIMMED "Combination display slider not at max, reflects combination meter settings only, not linked with headlight state";
CM_ SG_ 1553 ODOMETER "Unit is dependent upon units signal";
CM_ SG_ 1592 LOCK_STATUS_CHANGED "1 on rising edge of lock/unlocking";
CM_ SG_ 1592 LOCK_STATUS "The next 3 bits always seem to follow this signal.";
CM_ SG_ 1592 LOCKED_VIA_KEYFOB "1 for as long as car is locked with key fob or door handle touch";
VAL_ 295 GEAR 0 "P" 1 "R" 2 "N" 3 "D" 4 "B";
VAL_ 401 SETME_X3 3 "TSS 2.0" 1 "TSS 2.5 or 2022 RAV4" 0 "TSS 2.0 on Alphard, Highlander, NX";
VAL_ 467 PCM_FOLLOW_DISTANCE 1 "far" 2 "medium" 3 "close";
VAL_ 467 LOW_SPEED_LOCKOUT 2 "low speed locked" 1 "ok";
VAL_ 610 IPAS_STATE 5 "override" 3 "enabled" 1 "disabled";
VAL_ 610 LTA_STATE 25 "temporary_fault" 9 "temporary_fault2" 5 "active" 3 "lta_missing_unavailable" 1 "standby";
VAL_ 610 LKA_STATE 25 "temporary_fault" 17 "permanent_fault" 11 "lka_missing_unavailable2" 9 "temporary_fault2" 5 "active" 3 "lka_missing_unavailable" 1 "standby";
VAL_ 835 ALLOW_LONG_PRESS 2 "set speed increase by 5 speed units regardless" 1 "set speed increase by 1 speed unit on short press, 5 speed units on long press";
VAL_ 835 ACC_MALFUNCTION 1 "faulted" 0 "ok";
VAL_ 835 ACC_TYPE 2 "permanent low speed lockout" 1 "ok";
VAL_ 835 ACC_CUT_IN 1 "CUT-IN Detected" 0 "clear";
VAL_ 921 CRUISE_CONTROL_STATE 2 "disabled" 11 "hold" 10 "hold_waiting_user_cmd" 6 "enabled" 5 "faulted";
VAL_ 1041 PCS_INDICATOR 2 "PCS Faulted" 1 "PCS Turned Off By User" 0 "PCS Enabled";
VAL_ 1041 PCS_SENSITIVITY 64 "high sensitivity" 128 "mid sensitivity" 192 "low sensitivity" 0 "off";
VAL_ 1042 BARRIERS 3 "left" 2 "right" 1 "both" 0 "none";
VAL_ 1042 RIGHT_LINE 3 "orange" 2 "faded" 1 "solid" 0 "none";
VAL_ 1042 LEFT_LINE 3 "orange" 2 "faded" 1 "solid" 0 "none";
VAL_ 1042 LKAS_STATUS 1 "on" 0 "off";
VAL_ 1042 LDA_ALERT 3 "hold with continuous beep" 2 "LDA unavailable" 1 "hold" 0 "none";
VAL_ 1042 LDA_SENSITIVITY 2 "standard" 1 "high" 0 "undefined";
VAL_ 1042 LDA_SA_TOGGLE 2 "steering assist off" 1 "steering assist on";
VAL_ 1042 LDA_MESSAGES 4 "lda unavailable at this speed" 1 "lda unavailable below approx 50km/h" 0 "ok";
VAL_ 1042 LDA_ON_MESSAGE 2 "Lane Departure Alert Turned ON, Steering Assist Inactive" 1 "Lane Departure Alert Turned ON, Steering Assist Active" 0 "clear";
VAL_ 1042 TAKE_CONTROL 1 "take control" 0 "ok";
VAL_ 1042 LDA_FRONT_CAMERA_BLOCKED 1 "lda unavailable" 0 "ok";
VAL_ 1042 LANE_SWAY_BUZZER 3 "ok" 2 "beep twice" 1 "beep twice" 0 "ok";
VAL_ 1042 LANE_SWAY_WARNING 3 "ok" 2 "orange please take a break" 1 "prompt would you like to take a break" 0 "ok";
VAL_ 1161 TSGN1 1 "speed sign" 0 "none";
VAL_ 1161 SPLSGN2 15 "conditional blank" 4 "wet road" 5 "rain" 0 "none";
VAL_ 1161 TSGN2 1 "speed sign" 0 "none";
VAL_ 1162 TSGN3 0 "none" 1 "speed sign" 2 "0 unlimited" 7 "unlimited" 16 "highway" 17 "no highway" 18 "motorway" 19 "no motorway" 20 "in city" 21 "outside city" 22 "pedestrian area" 23 "no pedestrian area" 65 "no overtaking left" 66 "no overtaking right" 67 "overtaking allowed again" 81 "no right turn" 97 "stop" 105 "yield" 113 "stop" 114 "yield us" 129 "no entry" 138 "no entry tss2" 145 "do not enter";
VAL_ 1162 SPLSGN3 15 "conditional blank" 4 "wet road" 5 "rain" 0 "none";
VAL_ 1552 METER_SLIDER_LOW_BRIGHTNESS 1 "Low brightness mode, footwell lights off" 0 "Normal mode, footwell lights on";
VAL_ 1552 METER_SLIDER_DIMMED 1 "Dimmed" 0 "Not Dimmed";
VAL_ 1552 UNITS 1 "km (km/L)" 2 "km (L/100km)" 3 "miles (MPG US)" 4 "miles (MPG Imperial)";
VAL_ 1553 UNITS 1 "km" 2 "miles";
VAL_ 1556 TURN_SIGNALS 3 "none" 2 "right" 1 "left";
VAL_ 1592 LOCK_STATUS 0 "locked" 1 "unlocked";
